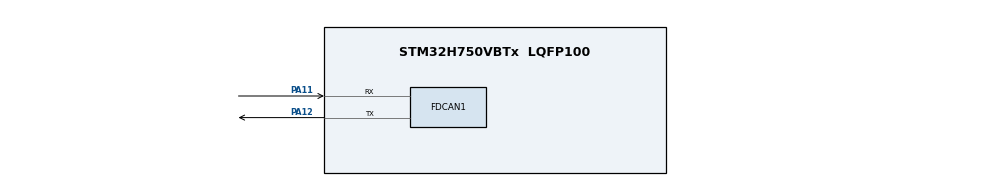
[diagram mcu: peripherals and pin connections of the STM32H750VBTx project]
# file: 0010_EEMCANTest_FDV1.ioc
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FDCAN1.AutoRetransmission=ENABLE
FDCAN1.CalculateBaudRateNominal=250000
FDCAN1.CalculateTimeBitNominal=4000
FDCAN1.CalculateTimeQuantumNominal=285.7142857142857
FDCAN1.NominalPrescaler=12
FDCAN1.NominalTimeSeg1=11
FDCAN1.TxFifoQueueElmtsNbr=24
Mcu.Family=STM32H7
Mcu.Name=STM32H750VBTx
Mcu.Package=LQFP100
NVIC.FDCAN1_IT0_IRQn=true\:0\:0\:false\:false\:true\:true\:true\:true
NVIC.FDCAN1_IT1_IRQn=true\:0\:0\:false\:false\:true\:true\:true\:true
NVIC.PriorityGroup=NVIC_PRIORITYGROUP_4
PA11.Mode=FDCAN_Activate
PA11.Signal=FDCAN1_RX
PA12.Mode=FDCAN_Activate
PA12.Signal=FDCAN1_TX
ProjectManager.HeapSize=0x2000
ProjectManager.StackSize=0x4000
ProjectManager.TargetToolchain=STM32CubeIDE
RCC.ADCFreq_Value=129000000
RCC.APB1Freq_Value=84000000
RCC.APB2Freq_Value=84000000
RCC.APB3Freq_Value=84000000
RCC.APB4Freq_Value=84000000
RCC.CortexFreq_Value=84000000
RCC.DIVM1=4
RCC.DIVN1=10
RCC.DIVQ1=4
RCC.HCLKFreq_Value=84000000
RCC.PLL2FRACN=0
RCC.PLL3FRACN=0
RCC.PLLFRACN=4096
RCC.SYSCLKFreq_VALUE=84000000
RCC.SYSCLKSource=RCC_SYSCLKSOURCE_PLLCLK
RCC.USBFreq_Value=42000000
board=custom

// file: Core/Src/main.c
/* USER CODE BEGIN Header */
/**
  ******************************************************************************
  * @file           : main.c
  * @brief          : Main program body
  ******************************************************************************
  * @attention
  *
  * Copyright (c) 2023 STMicroelectronics.
  * All rights reserved.
  *
  * This software is licensed under terms that can be found in the LICENSE file
  * in the root directory of this software component.
  * If no LICENSE file comes with this software, it is provided AS-IS.
  *
  ******************************************************************************
  */
/* USER CODE END Header */
#include "main.h"

/* USER CODE BEGIN Includes */

#include "EEMProtocol.h"
#include "EEMProtocol_Config.h"

/* USER CODE END Includes */

FDCAN_HandleTypeDef hfdcan1;

void SystemClock_Config(void);
static void MPU_Config(void);
static void MX_GPIO_Init(void);
static void MX_FDCAN1_Init(void);
/* USER CODE BEGIN PFP */

const uint8_t  testData[8] = { 0xFF , 0xFF , 0xFF , 0xFF , 0xFF , 0xFF , 0xFF , 0xFF };
const uint32_t testID	  = 0x1CFFFFFF;

EEM_Protocol_st			protocol;

extern BCM_Module_st	BCM_MSG;
/* HVAC module has been written Cpp language in order to arduino framework */
/* Simple computer protocol has written pyhton language */
extern BMS_Module_st	BMS_MSG;
extern MS1_Module_st	MS1_MSG;
extern MS2_Module_st	MS2_MSG;
extern ISO_Module_st	ISO_MSG;
extern TLM_Module_st	TLM_MSG;
extern YSB_Module_st	YSB_MSG;

/* USER CODE END PFP */

/* USER CODE BEGIN 0 */

// FDCAN1 Callback
void HAL_FDCAN_RxFifo0Callback(FDCAN_HandleTypeDef *hfdcan, uint32_t RxFifo0ITs)
{
  if((RxFifo0ITs & FDCAN_IT_RX_FIFO0_NEW_MESSAGE) != RESET)
  {
    /* Retreive Rx messages from RX FIFO0 */
    if (HAL_FDCAN_GetRxMessage(	&protocol.obj.fdHandle.hfdcanHandle ,
    							FDCAN_RX_FIFO0						,
								&protocol.obj.fdHandle.rxHeader 	,
								&protocol.obj.fdHandle.rxData[0] ) != HAL_OK)
    {
    /* Reception Error */
    Error_Handler();
    }

    //@NEW: @a.ertekin
    protocol.ops.EEM_RX(&protocol.obj.canPacket  			,
    					 protocol.obj.fdHandle.rxHeader		,
						 &protocol.obj.fdHandle.rxData[0]	);

    if (HAL_FDCAN_ActivateNotification(hfdcan, FDCAN_IT_RX_FIFO0_NEW_MESSAGE, 0) != HAL_OK)
    {
      /* Notification Error */
      Error_Handler();
    }

  }

}

void HAL_FDCAN_TxBufferCompleteCallback(FDCAN_HandleTypeDef *hfdcan, uint32_t BufferIndexes)
{
	return;
}

/* USER CODE END 0 */

int main(void)
{

  /* MPU Configuration--------------------------------------------------------*/
  MPU_Config();

  /* MCU Configuration--------------------------------------------------------*/

  /* Reset of all peripherals, Initializes the Flash interface and the Systick. */
  HAL_Init();

  /* Configure the system clock */
  SystemClock_Config();

  /* Initialize all configured peripherals */
  MX_GPIO_Init();
  MX_FDCAN1_Init();
  /* USER CODE BEGIN 2 */

  protocol.obj.fdHandle.hfdcanHandle = hfdcan1;
  protocol.ops = ops;

  protocol.ops.EEM_INIT(&protocol.obj);

  /* USER CODE END 2 */

  /* Infinite loop */
  while (1)
  {

    /* USER CODE BEGIN 3 */
	EEM_PERIODIC(&protocol.obj.canPacket);

	static uint32_t loopVal = 0;

	BCM_MSG.Message08.SPN.MS1_Speed = loopVal;
	loopVal++;

	memcpy(&protocol.obj.canPacket.DATA[0] , &BCM_MSG.Message08.payload[0] , 8);
	protocol.obj.canPacket.EXTENDED_ID.identifier = BCM_MSG.Message08_ID;

	protocol.ops.EEM_TX( &protocol.obj.canPacket , 0);
	HAL_Delay(100);

  }
  /* USER CODE END 3 */
}

void SystemClock_Config(void)
{
  RCC_OscInitTypeDef RCC_OscInitStruct = {0};
  RCC_ClkInitTypeDef RCC_ClkInitStruct = {0};

  /** Supply configuration update enable
  */
  HAL_PWREx_ConfigSupply(PWR_LDO_SUPPLY);

  /** Configure the main internal regulator output voltage
  */
  __HAL_PWR_VOLTAGESCALING_CONFIG(PWR_REGULATOR_VOLTAGE_SCALE3);

  while(!__HAL_PWR_GET_FLAG(PWR_FLAG_VOSRDY)) {}

  /** Initializes the RCC Oscillators according to the specified parameters
  * in the RCC_OscInitTypeDef structure.
  */
  RCC_OscInitStruct.OscillatorType = RCC_OSCILLATORTYPE_HSI;
  RCC_OscInitStruct.HSIState = RCC_HSI_DIV1;
  RCC_OscInitStruct.HSICalibrationValue = RCC_HSICALIBRATION_DEFAULT;
  RCC_OscInitStruct.PLL.PLLState = RCC_PLL_ON;
  RCC_OscInitStruct.PLL.PLLSource = RCC_PLLSOURCE_HSI;
  RCC_OscInitStruct.PLL.PLLM = 4;
  RCC_OscInitStruct.PLL.PLLN = 10;
  RCC_OscInitStruct.PLL.PLLP = 2;
  RCC_OscInitStruct.PLL.PLLQ = 4;
  RCC_OscInitStruct.PLL.PLLR = 2;
  RCC_OscInitStruct.PLL.PLLRGE = RCC_PLL1VCIRANGE_3;
  RCC_OscInitStruct.PLL.PLLVCOSEL = RCC_PLL1VCOMEDIUM;
  RCC_OscInitStruct.PLL.PLLFRACN = 4096;
  if (HAL_RCC_OscConfig(&RCC_OscInitStruct) != HAL_OK)
  {
    Error_Handler();
  }

  /** Initializes the CPU, AHB and APB buses clocks
  */
  RCC_ClkInitStruct.ClockType = RCC_CLOCKTYPE_HCLK|RCC_CLOCKTYPE_SYSCLK
                              |RCC_CLOCKTYPE_PCLK1|RCC_CLOCKTYPE_PCLK2
                              |RCC_CLOCKTYPE_D3PCLK1|RCC_CLOCKTYPE_D1PCLK1;
  RCC_ClkInitStruct.SYSCLKSource = RCC_SYSCLKSOURCE_PLLCLK;
  RCC_ClkInitStruct.SYSCLKDivider = RCC_SYSCLK_DIV1;
  RCC_ClkInitStruct.AHBCLKDivider = RCC_HCLK_DIV1;
  RCC_ClkInitStruct.APB3CLKDivider = RCC_APB3_DIV1;
  RCC_ClkInitStruct.APB1CLKDivider = RCC_APB1_DIV1;
  RCC_ClkInitStruct.APB2CLKDivider = RCC_APB2_DIV1;
  RCC_ClkInitStruct.APB4CLKDivider = RCC_APB4_DIV1;

  if (HAL_RCC_ClockConfig(&RCC_ClkInitStruct, FLASH_LATENCY_1) != HAL_OK)
  {
    Error_Handler();
  }
}

static void MX_FDCAN1_Init(void)
{

  hfdcan1.Instance = FDCAN1;
  hfdcan1.Init.FrameFormat = FDCAN_FRAME_CLASSIC;
  hfdcan1.Init.Mode = FDCAN_MODE_NORMAL;
  hfdcan1.Init.AutoRetransmission = ENABLE;
  hfdcan1.Init.TransmitPause = DISABLE;
  hfdcan1.Init.ProtocolException = DISABLE;
  hfdcan1.Init.NominalPrescaler = 12;
  hfdcan1.Init.NominalSyncJumpWidth = 1;
  hfdcan1.Init.NominalTimeSeg1 = 11;
  hfdcan1.Init.NominalTimeSeg2 = 2;
  hfdcan1.Init.DataPrescaler = 1;
  hfdcan1.Init.DataSyncJumpWidth = 1;
  hfdcan1.Init.DataTimeSeg1 = 1;
  hfdcan1.Init.DataTimeSeg2 = 1;
  hfdcan1.Init.MessageRAMOffset = 0;
  hfdcan1.Init.StdFiltersNbr = 0;
  hfdcan1.Init.ExtFiltersNbr = 3;
  hfdcan1.Init.RxFifo0ElmtsNbr = 0;
  hfdcan1.Init.RxFifo0ElmtSize = FDCAN_DATA_BYTES_8;
  hfdcan1.Init.RxFifo1ElmtsNbr = 0;
  hfdcan1.Init.RxFifo1ElmtSize = FDCAN_DATA_BYTES_8;
  hfdcan1.Init.RxBuffersNbr = 0;
  hfdcan1.Init.RxBufferSize = FDCAN_DATA_BYTES_8;
  hfdcan1.Init.TxEventsNbr = 0;
  hfdcan1.Init.TxBuffersNbr = 0;
  hfdcan1.Init.TxFifoQueueElmtsNbr = 24;
  hfdcan1.Init.TxFifoQueueMode = FDCAN_TX_FIFO_OPERATION;
  hfdcan1.Init.TxElmtSize = FDCAN_DATA_BYTES_8;
  if (HAL_FDCAN_Init(&hfdcan1) != HAL_OK)
  {
    Error_Handler();
  }

}

static void MX_GPIO_Init(void)
{

  /* GPIO Ports Clock Enable */
  __HAL_RCC_GPIOA_CLK_ENABLE();

}

/* MPU Configuration */

void MPU_Config(void)
{
  MPU_Region_InitTypeDef MPU_InitStruct = {0};

  /* Disables the MPU */
  HAL_MPU_Disable();

  /** Initializes and configures the Region and the memory to be protected
  */
  MPU_InitStruct.Enable = MPU_REGION_ENABLE;
  MPU_InitStruct.Number = MPU_REGION_NUMBER0;
  MPU_InitStruct.BaseAddress = 0x0;
  MPU_InitStruct.Size = MPU_REGION_SIZE_4GB;
  MPU_InitStruct.SubRegionDisable = 0x87;
  MPU_InitStruct.TypeExtField = MPU_TEX_LEVEL0;
  MPU_InitStruct.AccessPermission = MPU_REGION_NO_ACCESS;
  MPU_InitStruct.DisableExec = MPU_INSTRUCTION_ACCESS_DISABLE;
  MPU_InitStruct.IsShareable = MPU_ACCESS_SHAREABLE;
  MPU_InitStruct.IsCacheable = MPU_ACCESS_NOT_CACHEABLE;
  MPU_InitStruct.IsBufferable = MPU_ACCESS_NOT_BUFFERABLE;

  HAL_MPU_ConfigRegion(&MPU_InitStruct);
  /* Enables the MPU */
  HAL_MPU_Enable(MPU_PRIVILEGED_DEFAULT);

}

void Error_Handler(void)
{
  __disable_irq();
  while (1)
  {
  }
}
